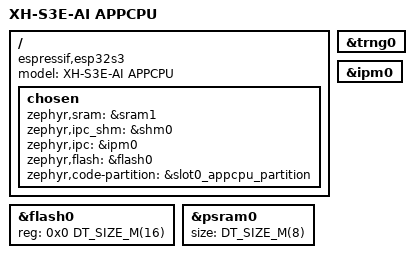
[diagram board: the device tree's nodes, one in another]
/*
 * Copyright (c) 2026 Anuj Deshpande
 *
 * SPDX-License-Identifier: Apache-2.0
 */
/dts-v1/;

#include <espressif/esp32s3/esp32s3.dtsi>
#include <espressif/partitions_0x0_amp_16M.dtsi>
#include "xh_s3e_ai-pinctrl.dtsi"

/ {
	model = "XH-S3E-AI APPCPU";
	compatible = "espressif,esp32s3";

	chosen {
		zephyr,sram = &sram1;
		zephyr,ipc_shm = &shm0;
		zephyr,ipc = &ipm0;
		zephyr,flash = &flash0;
		zephyr,code-partition = &slot0_appcpu_partition;
	};
};

&flash0 {
	reg = <0x0 DT_SIZE_M(16)>;
	ranges = <0x0 0x0 DT_SIZE_M(16)>;
};

&psram0 {
	size = <DT_SIZE_M(8)>;
};

&trng0 {
	status = "okay";
};

&ipm0 {
	status = "okay";
};
